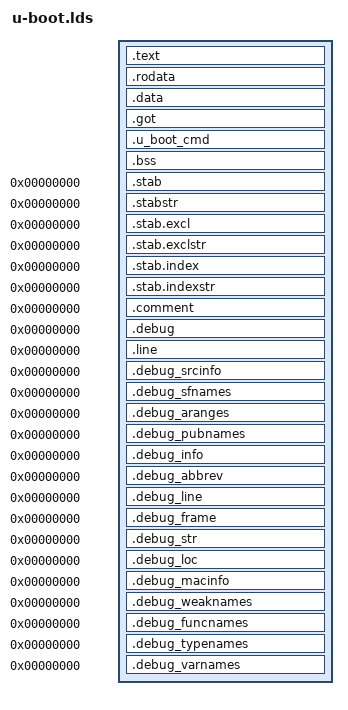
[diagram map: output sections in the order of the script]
/*
 * See file CREDITS for list of people who contributed to this
 * project.
 *
 * Some descriptions of such software. Copyright (c) 2008 WonderMedia Technologies, Inc.
 *
 * This program is free software: you can redistribute it and/or modify it under the
 * terms of the GNU General Public License as published by the Free Software Foundation,
 * either version 2 of the License, or (at your option) any later version.
 *
 * This program is distributed in the hope that it will be useful, but WITHOUT
 * ANY WARRANTY; without even the implied warranty of MERCHANTABILITY or FITNESS FOR A
 * PARTICULAR PURPOSE.  See the GNU General Public License for more details.
 * You should have received a copy of the GNU General Public License along with
 * this program.  If not, see <http://www.gnu.org/licenses/>.
 *
 * WonderMedia Technologies, Inc.
 * 10F, 529, Chung-Cheng Road, Hsin-Tien, Taipei 231, R.O.C.
 */

OUTPUT_FORMAT("elf32-littlearm", "elf32-littlearm", "elf32-littlearm")
OUTPUT_ARCH(arm)

ENTRY(_start)

SECTIONS
{
	. = 0x00000000;
	. = ALIGN(4);
	.text	:
	{
	  cpu/arm920t/start.o	(.text)
	  *(.text)
	}
	. = ALIGN(4);
	.rodata : { *(.rodata) }
	. = ALIGN(4);
	.data : { *(.data) }
	. = ALIGN(4);
	.got : { *(.got) }

	__u_boot_cmd_start = .;
	.u_boot_cmd : { *(.u_boot_cmd) }
	__u_boot_cmd_end = .;

	. = ALIGN(4);
	__bss_start = .;
	.bss : { *(.bss) }
	_end = .;

 	.stab 0 : { *(.stab) }
	.stabstr 0 : { *(.stabstr) }
 	.stab.excl 0 : { *(.stab.excl) }
	.stab.exclstr 0 : { *(.stab.exclstr) }
	.stab.index 0 : { *(.stab.index) }
	.stab.indexstr 0 : { *(.stab.indexstr) }
	.comment 0 : { *(.comment) }


	.debug          0 : { *(.debug) }
	.line           0 : { *(.line) }

	.debug_srcinfo  0 : { *(.debug_srcinfo) }
	.debug_sfnames  0 : { *(.debug_sfnames) }

	.debug_aranges  0 : { *(.debug_aranges) }
	.debug_pubnames 0 : { *(.debug_pubnames) }

	.debug_info     0 : { *(.debug_info) }
	.debug_abbrev   0 : { *(.debug_abbrev) }
	.debug_line     0 : { *(.debug_line) }
	.debug_frame    0 : { *(.debug_frame) }
	.debug_str      0 : { *(.debug_str) }
	.debug_loc      0 : { *(.debug_loc) }
	.debug_macinfo  0 : { *(.debug_macinfo) }

	.debug_weaknames 0 : { *(.debug_weaknames) }
	.debug_funcnames 0 : { *(.debug_funcnames) }
	.debug_typenames 0 : { *(.debug_typenames) }
	.debug_varnames  0 : { *(.debug_varnames) }

}
